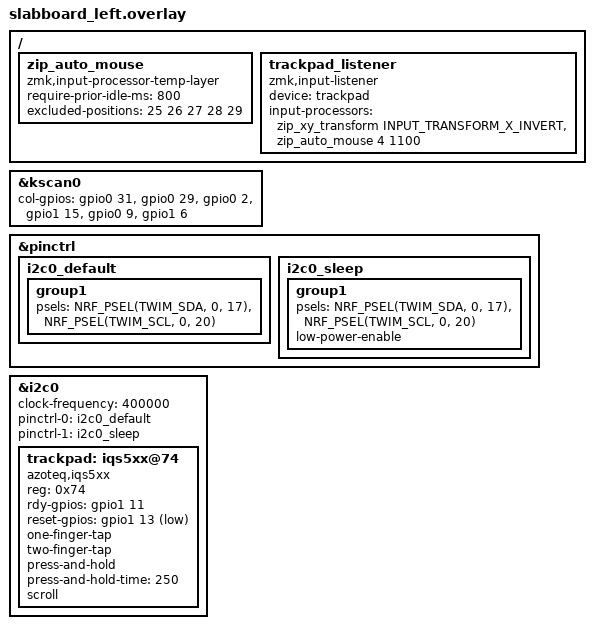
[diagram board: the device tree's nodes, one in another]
/*
 * SlabBoard — left half (BLE central, trackpad)
 *
 * SPDX-License-Identifier: MIT
 */

#include "slabboard.dtsi"

/* For &zip_xy_transform and INPUT_TRANSFORM_* -- see the trackpad listener. */
#include <input/processors.dtsi>
#include <dt-bindings/zmk/input_transform.h>

&kscan0 {
    /*
     * COL 0 (outer pinky) -> COL 5 (inner index).
     *
     * Reversed relative to the right half. Both halves are wired the same way
     * physically -- P1.06 is the INNER (index) column and P0.31 the OUTER
     * (pinky) column on each -- and one is flipped over, so they are mirror
     * images. Keymap columns run left to right across the whole board, so the
     * outer pinky is COL 0 here but COL 11 on the right; hence this list is
     * reversed and the right half's is not.
     *
     * Verified on hardware: with this list in P1.06-first order the left hand
     * typed its rows backwards.
     */
    col-gpios
        = <&gpio0 31 GPIO_ACTIVE_HIGH>   /* COL 0  P0.31  outer pinky */
        , <&gpio0 29 GPIO_ACTIVE_HIGH>   /* COL 1  P0.29 */
        , <&gpio0  2 GPIO_ACTIVE_HIGH>   /* COL 2  P0.02 */
        , <&gpio1 15 GPIO_ACTIVE_HIGH>   /* COL 3  P1.15 */
        , <&gpio0  9 GPIO_ACTIVE_HIGH>   /* COL 4  P0.09 */
        , <&gpio1  6 GPIO_ACTIVE_HIGH>   /* COL 5  P1.06  inner index */
        ;
};

/*
 * Azoteq TPS65 trackpad, on TWIM0.
 *
 * Driver: AYM1607/zmk-driver-azoteq-iqs5xx, pulled in by config/west.yml.
 * Its README lists the TPS65 as tested. The full property list lives in that
 * module at dts/bindings/input/azoteq,iqs5xx-common.yaml.
 *
 * i2c0 is safe to use here: it shares a peripheral ID with spi0, and this half
 * drives no SPI — the nice!view is on the right half's spi3.
 */
&pinctrl {
    i2c0_default: i2c0_default {
        group1 {
            psels = <NRF_PSEL(TWIM_SDA, 0, 17)>,    /* SDA  P0.17 */
                    <NRF_PSEL(TWIM_SCL, 0, 20)>;    /* SCL  P0.20 */
        };
    };

    i2c0_sleep: i2c0_sleep {
        group1 {
            psels = <NRF_PSEL(TWIM_SDA, 0, 17)>,
                    <NRF_PSEL(TWIM_SCL, 0, 20)>;
            low-power-enable;
        };
    };
};

&i2c0 {
    status = "okay";
    clock-frequency = <400000>;
    pinctrl-0 = <&i2c0_default>;
    pinctrl-1 = <&i2c0_sleep>;
    pinctrl-names = "default", "sleep";

    trackpad: iqs5xx@74 {
        compatible = "azoteq,iqs5xx";
        reg = <0x74>;
        status = "okay";

        rdy-gpios   = <&gpio1 11 GPIO_ACTIVE_HIGH>;   /* RDY  P1.11 */
        reset-gpios = <&gpio1 13 GPIO_ACTIVE_LOW>;    /* RST  P1.13 */

        /*
         * RST is active low on the IQS5xx, which is why this is GPIO_ACTIVE_LOW
         * (matching the driver's own example). At init the driver asserts it,
         * waits 1 ms, releases and waits 10 ms, so the pad starts from a known
         * state rather than whatever it was left in.
         */

        /*
         * No axis flags here on purpose. The IQS5xx's own XY_CONFIG_0 bits do
         * NOT behave as the driver's header claims on this part, measured over
         * three builds (finger direction -> pointer direction):
         *
         *   written 0x00 (no flags)  up->up  down->down  left->right right->left
         *   written 0x01 (flip-x)    up->left down->right left->down right->up
         *   written 0x07 (all three) up->right down->left left->down right->up
         *
         * Taking 0x00 as the untransformed mounting, 0x01 acts as an X/Y SWAP
         * and 0x07 as swap+flipY -- neither is what azoteq,iqs5xx-common.yaml
         * documents, and no ordering of flip-then-swap reproduces it. The
         * driver writes the bits to XY_CONFIG_0 (0x0669) and reads back the
         * RELATIVE registers REL_X/REL_Y (0x0012/0x0014); the chip evidently
         * does not apply that register to the relative path the way the
         * absolute one is documented.
         *
         * So leave the chip untouched -- 0x00 is the one state whose behaviour
         * is actually known -- and correct the axis in ZMK instead, on the
         * trackpad listener below. The mounting needs exactly an X inversion.
         */

        one-finger-tap;
        two-finger-tap;
        press-and-hold;
        press-and-hold-time = <250>;
        scroll;
    };
};

/*
 * Mouse layer auto-activation.
 *
 * zip_auto_mouse raises keymap layer 4 (Mouse) whenever the trackpad reports
 * movement and drops it again after a quiet period, so the left-hand home row
 * is already mouse buttons by the time a finger lands on the pad. The TPS65's
 * own click-and-drag gesture is unreliable, which is the point of the layer.
 *
 * Named and shaped to match ergohaven-zmk-config's velvet_v3_ui, which uses
 * the same zmk,input-processor-temp-layer under this name. Values track that
 * config except where a trackpad differs from a trackball:
 *
 *  - require-prior-idle-ms = 800 is velvet's tested value, and matters MORE
 *    here: a trackball only emits events when deliberately spun, while a pad
 *    fires on any brush or resting finger. Keeps the home row from silently
 *    turning into mouse buttons mid-sentence.
 *  - the 1100 ms timeout is longer than velvet's 700. With a ball you spin and
 *    click in one motion; with a pad you often move, lift, pause to aim, then
 *    click -- and at 700 ms that pause drops the layer and F types "f".
 *    Provisional: tune on hardware.
 *  - excluded-positions deliberately does NOT match velvet's empty list. Any
 *    key press drops the layer, and ZMK routes a key release to the binding
 *    resolved at PRESS time, so a single click or drag survives an empty list.
 *    But pressing a second button while holding the first would fall through
 *    to the base layer and type a letter. Listing 25..29 (A S D F G) closes
 *    that at no cost.
 *
 * Layer 4 is also bound to &mo 4 on the right thumb for deliberate use.
 */
/ {
    zip_auto_mouse: zip_auto_mouse {
        compatible = "zmk,input-processor-temp-layer";
        #input-processor-cells = <2>;
        require-prior-idle-ms = <800>;
        excluded-positions = <25 26 27 28 29>;
    };
};

/ {
    trackpad_listener: trackpad_listener {
        compatible = "zmk,input-listener";
        device = <&trackpad>;

        /*
         * Axis correction lives here, not on the trackpad node -- see the long
         * comment there for why the chip's own flags are unusable.
         *
         * The pad reports left/right inverted and up/down correct, so a single
         * X inversion squares it up. zip_xy_transform works on INPUT_EV_REL
         * with x-codes = INPUT_REL_X, and X_INVERT simply negates the value of
         * matching events (app/src/pointing/input_processor_transform.c), so
         * this is unambiguous -- there is no swap in play whose ordering could
         * change the result.
         * See https://zmk.dev/docs/keymaps/input-processors
         */
        input-processors
            = <&zip_xy_transform INPUT_TRANSFORM_X_INVERT>
            , <&zip_auto_mouse 4 1100>
            ;
    };
};
